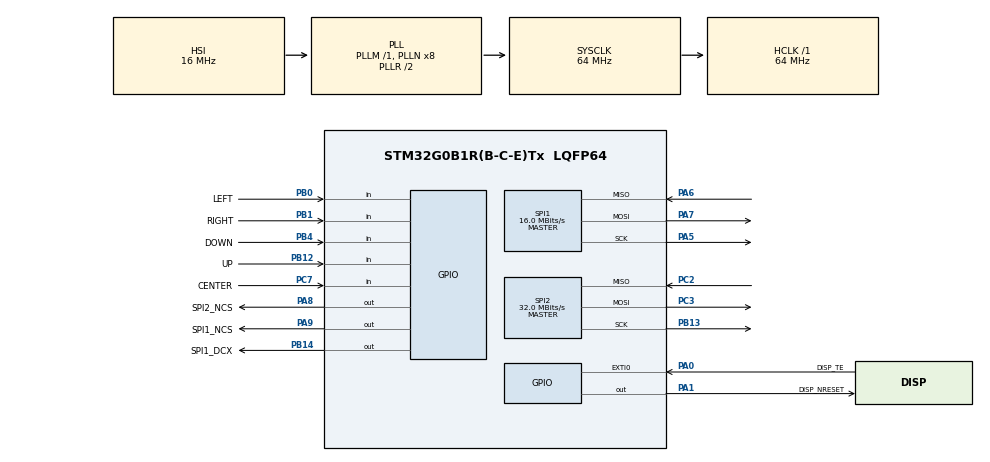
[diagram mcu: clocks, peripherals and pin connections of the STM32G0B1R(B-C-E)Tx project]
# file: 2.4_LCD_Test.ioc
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Dma.Request0=SPI1_TX
Dma.Request1=SPI2_TX
Dma.Request2=SPI2_RX
Dma.SPI1_TX.0.Direction=DMA_MEMORY_TO_PERIPH
Dma.SPI1_TX.0.EventEnable=DISABLE
Dma.SPI1_TX.0.Instance=DMA1_Channel1
Dma.SPI1_TX.0.MemDataAlignment=DMA_MDATAALIGN_HALFWORD
Dma.SPI1_TX.0.MemInc=DMA_MINC_ENABLE
Dma.SPI1_TX.0.Mode=DMA_NORMAL
Dma.SPI1_TX.0.PeriphDataAlignment=DMA_PDATAALIGN_HALFWORD
Dma.SPI1_TX.0.PeriphInc=DMA_PINC_DISABLE
Dma.SPI1_TX.0.Polarity=HAL_DMAMUX_REQ_GEN_RISING
Dma.SPI1_TX.0.Priority=DMA_PRIORITY_HIGH
Dma.SPI1_TX.0.RequestNumber=1
Dma.SPI1_TX.0.SignalID=NONE
Dma.SPI1_TX.0.SyncEnable=DISABLE
Dma.SPI1_TX.0.SyncPolarity=HAL_DMAMUX_SYNC_NO_EVENT
Dma.SPI1_TX.0.SyncRequestNumber=1
Dma.SPI1_TX.0.SyncSignalID=NONE
Dma.SPI2_RX.2.Direction=DMA_PERIPH_TO_MEMORY
Dma.SPI2_RX.2.EventEnable=DISABLE
Dma.SPI2_RX.2.Instance=DMA1_Channel2
Dma.SPI2_RX.2.MemDataAlignment=DMA_MDATAALIGN_BYTE
Dma.SPI2_RX.2.MemInc=DMA_MINC_ENABLE
Dma.SPI2_RX.2.Mode=DMA_NORMAL
Dma.SPI2_RX.2.PeriphDataAlignment=DMA_PDATAALIGN_BYTE
Dma.SPI2_RX.2.PeriphInc=DMA_PINC_DISABLE
Dma.SPI2_RX.2.Polarity=HAL_DMAMUX_REQ_GEN_RISING
Dma.SPI2_RX.2.Priority=DMA_PRIORITY_MEDIUM
Dma.SPI2_RX.2.RequestNumber=1
Dma.SPI2_RX.2.SignalID=NONE
Dma.SPI2_RX.2.SyncEnable=DISABLE
Dma.SPI2_RX.2.SyncPolarity=HAL_DMAMUX_SYNC_NO_EVENT
Dma.SPI2_RX.2.SyncRequestNumber=1
Dma.SPI2_RX.2.SyncSignalID=NONE
Dma.SPI2_TX.1.Direction=DMA_MEMORY_TO_PERIPH
Dma.SPI2_TX.1.EventEnable=DISABLE
Dma.SPI2_TX.1.Instance=DMA1_Channel3
Dma.SPI2_TX.1.MemDataAlignment=DMA_MDATAALIGN_BYTE
Dma.SPI2_TX.1.MemInc=DMA_MINC_ENABLE
Dma.SPI2_TX.1.Mode=DMA_NORMAL
Dma.SPI2_TX.1.PeriphDataAlignment=DMA_PDATAALIGN_BYTE
Dma.SPI2_TX.1.PeriphInc=DMA_PINC_DISABLE
Dma.SPI2_TX.1.Polarity=HAL_DMAMUX_REQ_GEN_RISING
Dma.SPI2_TX.1.Priority=DMA_PRIORITY_LOW
Dma.SPI2_TX.1.RequestNumber=1
Dma.SPI2_TX.1.SignalID=NONE
Dma.SPI2_TX.1.SyncEnable=DISABLE
Dma.SPI2_TX.1.SyncPolarity=HAL_DMAMUX_SYNC_NO_EVENT
Dma.SPI2_TX.1.SyncRequestNumber=1
Dma.SPI2_TX.1.SyncSignalID=NONE
Mcu.Family=STM32G0
Mcu.Name=STM32G0B1R(B-C-E)Tx
Mcu.Package=LQFP64
NVIC.DMA1_Channel1_IRQn=true\:0\:0\:false\:false\:true\:false\:true\:true
NVIC.DMA1_Channel2_3_IRQn=true\:0\:0\:false\:false\:true\:false\:true\:true
NVIC.EXTI0_1_IRQn=true\:0\:0\:false\:false\:true\:true\:true\:true
PA0.GPIO_Label=DISP_TE
PA0.Signal=GPXTI0
PA1.GPIO_Label=DISP_NRESET
PA1.GPIO_Speed=GPIO_SPEED_FREQ_HIGH
PA1.PinState=GPIO_PIN_SET
PA1.Signal=GPIO_Output
PA5.GPIO_Speed=GPIO_SPEED_FREQ_VERY_HIGH
PA5.Mode=Full_Duplex_Master
PA5.Signal=SPI1_SCK
PA6.Mode=Full_Duplex_Master
PA6.Signal=SPI1_MISO
PA7.GPIO_Speed=GPIO_SPEED_FREQ_VERY_HIGH
PA7.Mode=Full_Duplex_Master
PA7.Signal=SPI1_MOSI
PA8.GPIO_Label=SPI2_NCS
PA8.GPIO_Speed=GPIO_SPEED_FREQ_VERY_HIGH
PA8.PinState=GPIO_PIN_SET
PA8.Signal=GPIO_Output
PA9.GPIO_Label=SPI1_NCS
PA9.GPIO_Speed=GPIO_SPEED_FREQ_VERY_HIGH
PA9.PinState=GPIO_PIN_SET
PA9.Signal=GPIO_Output
PB0.GPIO_Label=LEFT
PB0.GPIO_PuPd=GPIO_PULLUP
PB0.Signal=GPIO_Input
PB1.GPIO_Label=RIGHT
PB1.GPIO_PuPd=GPIO_PULLUP
PB1.Signal=GPIO_Input
PB12.GPIO_Label=UP
PB12.GPIO_PuPd=GPIO_PULLUP
PB12.Signal=GPIO_Input
PB13.GPIO_Speed=GPIO_SPEED_FREQ_VERY_HIGH
PB13.Mode=Full_Duplex_Master
PB13.Signal=SPI2_SCK
PB14.GPIO_Label=SPI1_DCX
PB14.GPIO_Speed=GPIO_SPEED_FREQ_VERY_HIGH
PB14.Signal=GPIO_Output
PB4.GPIO_Label=DOWN
PB4.GPIO_PuPd=GPIO_PULLUP
PB4.Signal=GPIO_Input
PC2.Mode=Full_Duplex_Master
PC2.Signal=SPI2_MISO
PC3.GPIO_Speed=GPIO_SPEED_FREQ_VERY_HIGH
PC3.Mode=Full_Duplex_Master
PC3.Signal=SPI2_MOSI
PC7.GPIO_Label=CENTER
PC7.GPIO_PuPd=GPIO_PULLUP
PC7.Signal=GPIO_Input
ProjectManager.HeapSize=0x200
ProjectManager.StackSize=0x400
ProjectManager.TargetToolchain=CMake
RCC.ADCFreq_Value=64000000
RCC.AHBFreq_Value=64000000
RCC.CortexFreq_Value=64000000
RCC.EXTERNAL_CLOCK_VALUE=48000
RCC.HCLKFreq_Value=64000000
RCC.HSE_VALUE=8000000
RCC.HSI48_VALUE=48000000
RCC.HSI_VALUE=16000000
RCC.LSE_VALUE=32768
RCC.SYSCLKFreq_VALUE=64000000
RCC.SYSCLKSource=RCC_SYSCLKSOURCE_PLLCLK
RCC.USBFreq_Value=48000000
RCC.VCOOutputFreq_Value=128000000
SPI1.BaudRatePrescaler=SPI_BAUDRATEPRESCALER_4
SPI1.CalculateBaudRate=16.0 MBits/s
SPI1.DataSize=SPI_DATASIZE_8BIT
SPI1.Direction=SPI_DIRECTION_2LINES
SPI1.Mode=SPI_MODE_MASTER
SPI1.VirtualType=VM_MASTER
SPI2.BaudRatePrescaler=SPI_BAUDRATEPRESCALER_2
SPI2.CalculateBaudRate=32.0 MBits/s
SPI2.DataSize=SPI_DATASIZE_8BIT
SPI2.Direction=SPI_DIRECTION_2LINES
SPI2.Mode=SPI_MODE_MASTER
SPI2.VirtualType=VM_MASTER
STMicroelectronics.X-CUBE-TOUCHGFX.4.26.1.ApplicationCcGraphicsJjApplication=TouchGFXOoGenerator
STMicroelectronics.X-CUBE-TOUCHGFX.4.26.1.tgfx_block_size=9600
STMicroelectronics.X-CUBE-TOUCHGFX.4.26.1.tgfx_buffering_strategy=Partial
STMicroelectronics.X-CUBE-TOUCHGFX.4.26.1.tgfx_custom_height=320
STMicroelectronics.X-CUBE-TOUCHGFX.4.26.1.tgfx_custom_width=240
STMicroelectronics.X-CUBE-TOUCHGFX.4.26.1.tgfx_datareader=Enabled
STMicroelectronics.X-CUBE-TOUCHGFX.4.26.1.tgfx_datareader_dma_transfersize=16
STMicroelectronics.X-CUBE-TOUCHGFX.4.26.1.tgfx_datareader_mem_size=0x00800000
STMicroelectronics.X-CUBE-TOUCHGFX.4.26.1.tgfx_number_of_blocks=2
STMicroelectronics.X-CUBE-TOUCHGFX.4.26.1_IsPackSelfContextualization=true
VP_CRC_VS_CRC.Mode=CRC_Activate
VP_STMicroelectronics.X-CUBE-TOUCHGFX_VS_GraphicsJjApplication_4.26.1.Mode=GraphicsJjApplication
VP_SYS_VS_DBSignals.Mode=DisableDeadBatterySignals
board=custom

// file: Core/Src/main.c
/* USER CODE BEGIN Header */
/**
  ******************************************************************************
  * @file           : main.c
  * @brief          : Main program body
  ******************************************************************************
  * @attention
  *
  * Copyright (c) 2026 STMicroelectronics.
  * All rights reserved.
  *
  * This software is licensed under terms that can be found in the LICENSE file
  * in the root directory of this software component.
  * If no LICENSE file comes with this software, it is provided AS-IS.
  *
  ******************************************************************************
  */
/* USER CODE END Header */
#include "main.h"
#include "crc.h"
#include "dma.h"
#include "spi.h"
#include "gpio.h"
#include "app_touchgfx.h"

/* USER CODE BEGIN Includes */
#include "display_driver.h"
#include "flash_driver.h"
/* USER CODE END Includes */

void SystemClock_Config(void);

int main(void)
{

  /* MCU Configuration--------------------------------------------------------*/

  /* Reset of all peripherals, Initializes the Flash interface and the Systick. */
  HAL_Init();

  /* Configure the system clock */
  SystemClock_Config();

  /* Initialize all configured peripherals */
  MX_GPIO_Init();
  MX_DMA_Init();
  MX_SPI1_Init();
  MX_SPI2_Init();
  MX_CRC_Init();
  MX_TouchGFX_Init();
  /* USER CODE BEGIN 2 */
  if (FLASH_DRIVER_Init() == 0)
  {
    /* MX25L6433F not answering (JEDEC ID mismatch) - check wiring/power.
     * UI assets live in this flash, so there is no point in continuing. */
    Error_Handler();
  }
  LCD_Init();
  /* USER CODE END 2 */

  /* Infinite loop */
  while (1)
  {

  MX_TouchGFX_Process();
  }
}

void SystemClock_Config(void)
{
  RCC_OscInitTypeDef RCC_OscInitStruct = {0};
  RCC_ClkInitTypeDef RCC_ClkInitStruct = {0};

  /** Configure the main internal regulator output voltage
  */
  HAL_PWREx_ControlVoltageScaling(PWR_REGULATOR_VOLTAGE_SCALE1);

  /** Initializes the RCC Oscillators according to the specified parameters
  * in the RCC_OscInitTypeDef structure.
  */
  RCC_OscInitStruct.OscillatorType = RCC_OSCILLATORTYPE_HSI;
  RCC_OscInitStruct.HSIState = RCC_HSI_ON;
  RCC_OscInitStruct.HSIDiv = RCC_HSI_DIV1;
  RCC_OscInitStruct.HSICalibrationValue = RCC_HSICALIBRATION_DEFAULT;
  RCC_OscInitStruct.PLL.PLLState = RCC_PLL_ON;
  RCC_OscInitStruct.PLL.PLLSource = RCC_PLLSOURCE_HSI;
  RCC_OscInitStruct.PLL.PLLM = RCC_PLLM_DIV1;
  RCC_OscInitStruct.PLL.PLLN = 8;
  RCC_OscInitStruct.PLL.PLLP = RCC_PLLP_DIV2;
  RCC_OscInitStruct.PLL.PLLQ = RCC_PLLQ_DIV2;
  RCC_OscInitStruct.PLL.PLLR = RCC_PLLR_DIV2;
  if (HAL_RCC_OscConfig(&RCC_OscInitStruct) != HAL_OK)
  {
    Error_Handler();
  }

  /** Initializes the CPU, AHB and APB buses clocks
  */
  RCC_ClkInitStruct.ClockType = RCC_CLOCKTYPE_HCLK|RCC_CLOCKTYPE_SYSCLK
                              |RCC_CLOCKTYPE_PCLK1;
  RCC_ClkInitStruct.SYSCLKSource = RCC_SYSCLKSOURCE_PLLCLK;
  RCC_ClkInitStruct.AHBCLKDivider = RCC_SYSCLK_DIV1;
  RCC_ClkInitStruct.APB1CLKDivider = RCC_HCLK_DIV1;

  if (HAL_RCC_ClockConfig(&RCC_ClkInitStruct, FLASH_LATENCY_2) != HAL_OK)
  {
    Error_Handler();
  }
}

void Error_Handler(void)
{
  __disable_irq();
  while (1)
  {
  }
}
